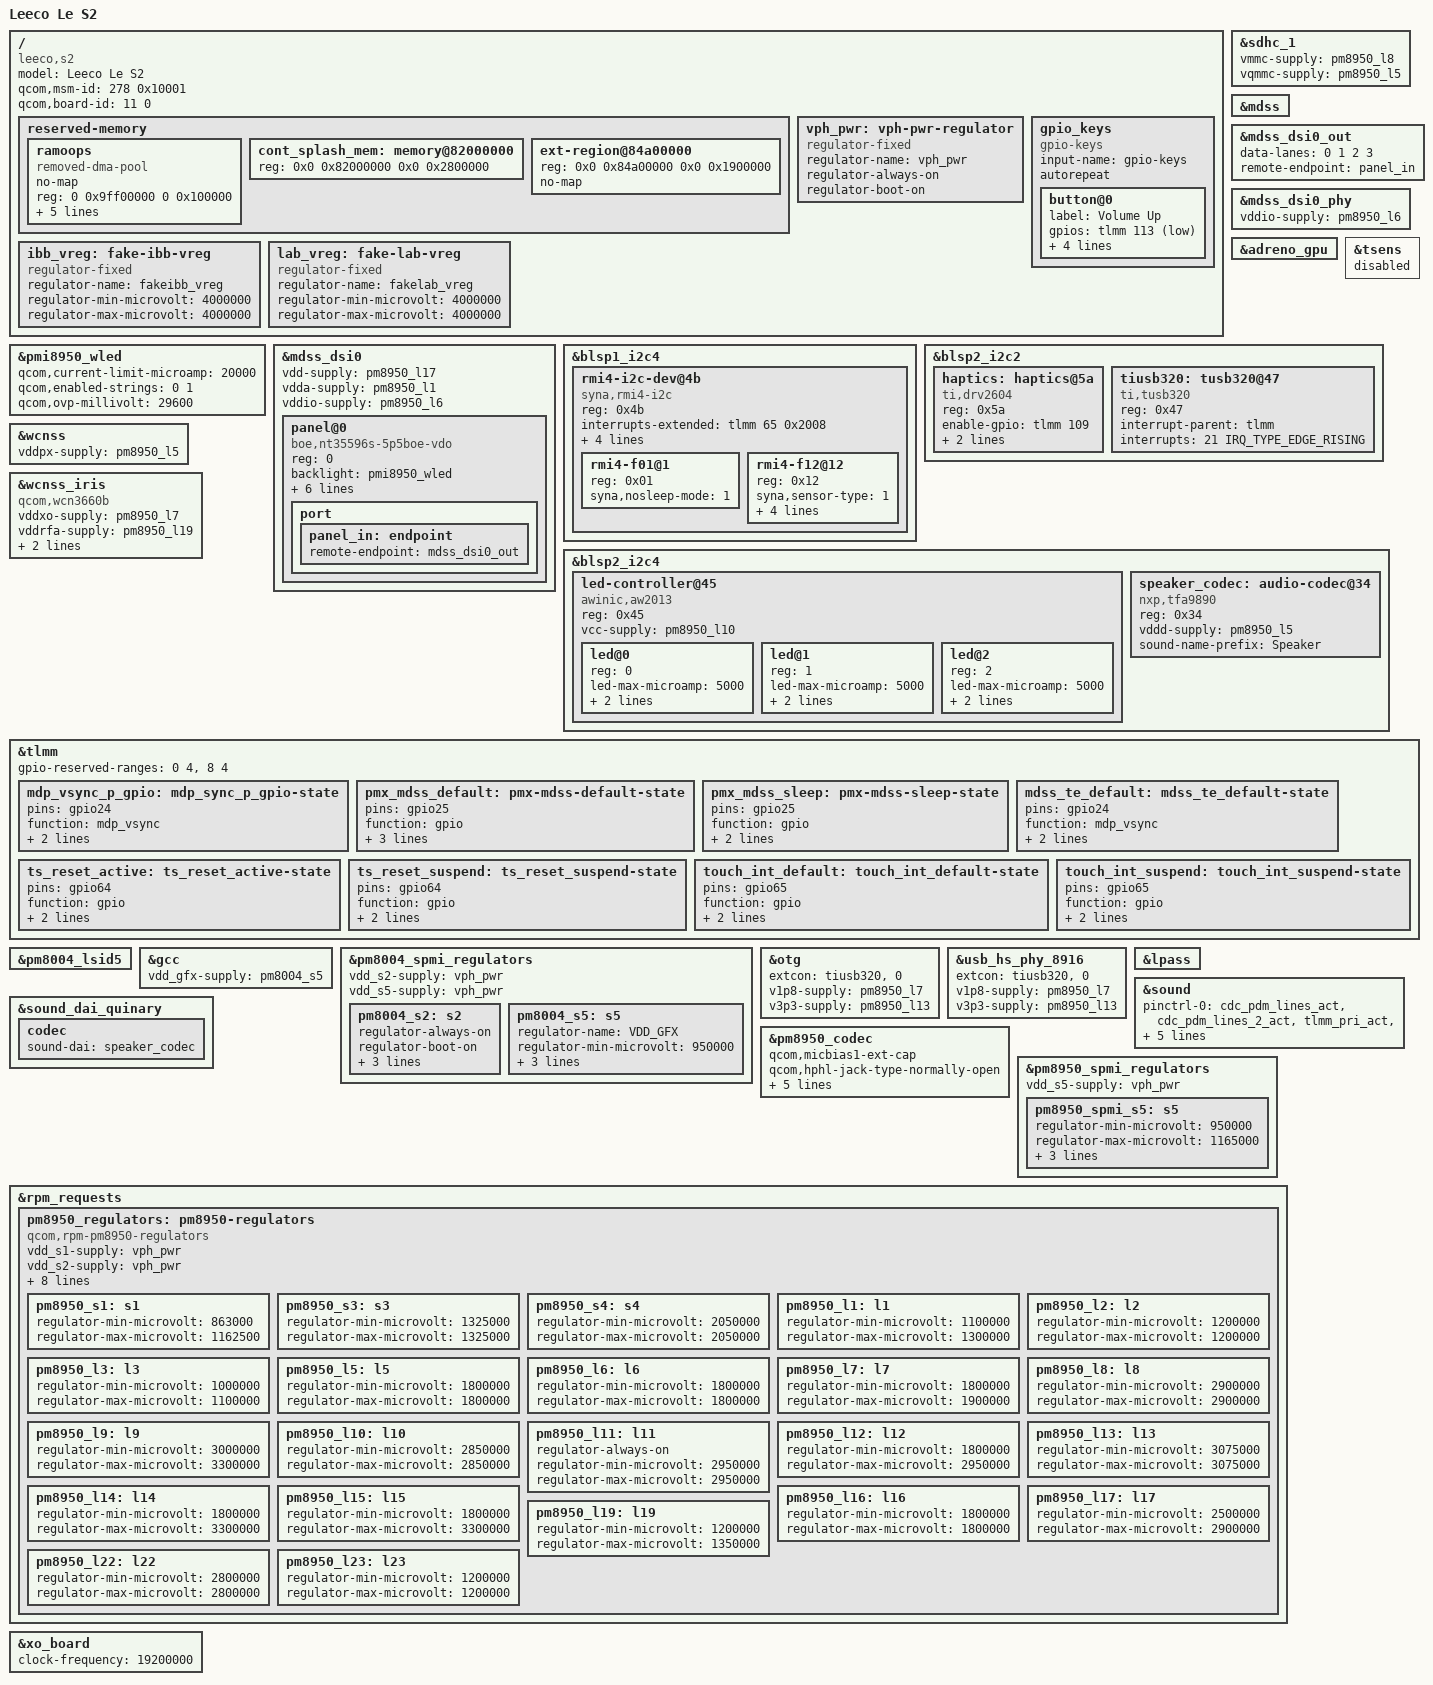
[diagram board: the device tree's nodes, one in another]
// SPDX-License-Identifier: BSD-3-Clause
/dts-v1/;
#include "msm8976.dtsi"
#include "pm8950.dtsi"
#include "pm8004.dtsi"
#include "pmi8950.dtsi"
#include <dt-bindings/interrupt-controller/irq.h>
#include <dt-bindings/gpio/gpio.h>
#include <dt-bindings/input/gpio-keys.h>
#include <dt-bindings/input/input.h>
#include <dt-bindings/input/linux-event-codes.h>
#include <dt-bindings/pinctrl/qcom,pmic-gpio.h>
#include <dt-bindings/leds/common.h>
#include <dt-bindings/input/ti-drv260x.h>

/ {
	model = "Leeco Le S2";
	compatible = "leeco,s2", "qcom,msm8976";

	qcom,msm-id = <278 0x10001>;
	qcom,board-id = <11 0>;

	reserved-memory {
		ramoops {
			compatible = "removed-dma-pool", "ramoops";
			no-map;
			reg = <0 0x9ff00000 0 0x100000>;
			record-size = <0x10000>;
			console-size = <0x60000>;
			ftrace-size = <0x10000>;
			pmsg-size = <0x20000>;
			ecc-size = <16>;
			status = "okay";
		};

		/delete-node/ memory@83000000;
		
		cont_splash_mem: memory@82000000 {
			reg = <0x0 0x82000000 0x0 0x2800000>;
		};
		
		/delete-node/ ext-region@85b00000;
		 ext-region@84a00000 {
			reg = <0x0 0x84a00000 0x0 0x1900000>;
			no-map;
		};

	};

	vph_pwr: vph-pwr-regulator {
		compatible = "regulator-fixed";
		regulator-name = "vph_pwr";
		regulator-always-on;
		regulator-boot-on;
	};

	gpio_keys {
		compatible = "gpio-keys";
		input-name = "gpio-keys";
		#address-cells = <1>;
		#size-cells = <0>;
		autorepeat;

		button@0 {
			label = "Volume Up";
			gpios = <&tlmm 113 GPIO_ACTIVE_LOW>;
			linux,input-type = <EV_KEY>;
			linux,code = <KEY_VOLUMEUP>;
			wakeup-source;
			debounce-interval = <15>;
		};
	};
	ibb_vreg: fake-ibb-vreg {
		compatible = "regulator-fixed";
		regulator-name = "fakeibb_vreg";
		regulator-min-microvolt = <4000000>;
		regulator-max-microvolt = <4000000>;
	};
	lab_vreg: fake-lab-vreg {
		compatible = "regulator-fixed";
		regulator-name = "fakelab_vreg";
		regulator-min-microvolt = <4000000>;
		regulator-max-microvolt = <4000000>;
	};

};

&sdhc_1 {
	vmmc-supply = <&pm8950_l8>;
	vqmmc-supply = <&pm8950_l5>;
	
	status = "okay";
};

&pmi8950_wled {
	status = "okay";

	qcom,current-limit-microamp = <20000>;
	qcom,enabled-strings = <0 1>;
	qcom,ovp-millivolt = <29600>;
};
&mdss {
	status = "okay";
};

&mdss_dsi0 {
	panel@0 {
		compatible = "boe,nt35596s-5p5boe-vdo";
		reg = <0>;
		backlight = <&pmi8950_wled>;

		supply-names = "vsp", "vsn";
		vsp-supply = <&lab_vreg>;
		vsn-supply = <&ibb_vreg>;

		reset-gpios = <&tlmm 25 GPIO_ACTIVE_LOW>;

		pinctrl-names = "default", "sleep";
		pinctrl-0 = <&pmx_mdss_default &mdss_te_default>;
		pinctrl-1 = <&pmx_mdss_sleep &mdss_te_default>;

		port {
			panel_in: endpoint {
				remote-endpoint = <&mdss_dsi0_out>;
			};
		};
	};
};


&mdss_dsi0_out {
	data-lanes = <0 1 2 3>;
	remote-endpoint = <&panel_in>;
};


&mdss_dsi0_phy {
	status = "okay";
	vddio-supply = <&pm8950_l6>;
};

&mdss_dsi0 {

	vdd-supply = <&pm8950_l17>;
	vdda-supply = <&pm8950_l1>;
	vddio-supply = <&pm8950_l6>;
};

&adreno_gpu {
	status = "okay";
};

&tsens {
status = "disabled";
};

&blsp1_i2c4 {
	status = "okay";

	rmi4-i2c-dev@4b {
		reg = <0x4b>;
		compatible = "syna,rmi4-i2c";
		interrupts-extended = <&tlmm 65 0x2008>;
		#address-cells = <1>;
		#size-cells = <0>;

		vdd-supply = <&pm8950_l17>;
		vio-supply = <&pm8950_l6>;
	
		syna,reset-delay-ms = <100>;
		syna,startup-delay-ms = <500>;
		rmi4-f01@1 {
			reg = <0x01>;
			syna,nosleep-mode = <1>;
		};

		rmi4-f12@12 {
			reg = <0x12>;
			syna,sensor-type = <1>;
			syna,clip-x-low = <0>;
			syna,clip-x-high = <1080>;
			syna,clip-y-low = <0>;
			syna,clip-y-high = <1920>;
		};
	};
};

&blsp2_i2c2 {

	status = "okay";
	
	haptics: haptics@5a {
		compatible = "ti,drv2604";
		reg = <0x5a>;
		enable-gpio = <&tlmm 109 GPIO_ACTIVE_HIGH>;
		mode = <DRV260X_LRA_MODE>;
		library-sel = <DRV260X_LIB_LRA>;
	};

	tiusb320: tusb320@47 {
		compatible = "ti,tusb320";
		reg = <0x47>;
		interrupt-parent = <&tlmm>;
		interrupts = <21 IRQ_TYPE_EDGE_RISING>;
        };
};

&blsp2_i2c4 {
	status = "okay";
	led-controller@45 {
		#address-cells = <1>;
		#size-cells = <0>;

		compatible = "awinic,aw2013";
		reg = <0x45>;
		vcc-supply = <&pm8950_l10>;

		led@0 {
			reg = <0>;
			led-max-microamp = <5000>;
			function = LED_FUNCTION_INDICATOR;
			color = <LED_COLOR_ID_RED>;
		};
		led@1 {
			reg = <1>;
			led-max-microamp = <5000>;
			function = LED_FUNCTION_INDICATOR;
			color = <LED_COLOR_ID_GREEN>;
		};
		led@2 {
			reg = <2>;
			led-max-microamp = <5000>;
			function = LED_FUNCTION_INDICATOR;
			color = <LED_COLOR_ID_BLUE>;
		};
	};
	
	speaker_codec: audio-codec@34 {
		compatible = "nxp,tfa9890";
		reg = <0x34>;
		vddd-supply = <&pm8950_l5>;
		sound-name-prefix = "Speaker";
		#sound-dai-cells = <0>;
	};
};


&wcnss {
	status = "okay";
	vddpx-supply = <&pm8950_l5>;
};

&wcnss_iris {
	compatible = "qcom,wcn3660b";

	vddxo-supply = <&pm8950_l7>;
	vddrfa-supply = <&pm8950_l19>;
	vddpa-supply = <&pm8950_l9>;
	vdddig-supply = <&pm8950_l5>;
};

&tlmm {
	gpio-reserved-ranges = <0 4>, <8 4>;

	mdp_vsync_p_gpio: mdp_sync_p_gpio-state {
		pins = "gpio24";
		function = "mdp_vsync";
		drive-strength = <2>;
		bias-disable;
	};


	pmx_mdss_default: pmx-mdss-default-state {
		pins = "gpio25";
		function = "gpio";
		drive-strength = <8>;
		bias-disable;
		output-high;
	};

	pmx_mdss_sleep: pmx-mdss-sleep-state {
		pins = "gpio25";
		function = "gpio";
		drive-strength = <2>;
		bias-pull-down;
	};

	mdss_te_default: mdss_te_default-state {
			pins = "gpio24";
			function = "mdp_vsync";
			drive-strength = <2>;
			bias-pull-down;
		};
		
	ts_reset_active: ts_reset_active-state {
		pins = "gpio64";
		function = "gpio";
		drive-strength = <8>;
		bias-pull-up;
	};

	ts_reset_suspend: ts_reset_suspend-state {
		pins = "gpio64";
		function = "gpio";
		drive-strength = <2>;
		bias-pull-down;
	};

	touch_int_default: touch_int_default-state {
		pins = "gpio65";
		function = "gpio";
		drive-strength = <8>;
		bias-pull-up;
	};

	touch_int_suspend: touch_int_suspend-state {
		pins = "gpio65";
		function = "gpio";
		drive-strength = <2>;
		bias-pull-down;
	};
};

&pm8004_lsid5 {
	status = "okay";
};

&gcc {
	vdd_gfx-supply = <&pm8004_s5>;
};

&pm8004_spmi_regulators {
	vdd_s2-supply = <&vph_pwr>;
	vdd_s5-supply = <&vph_pwr>;
	status = "okay";
	
	pm8004_s2: s2 {
		regulator-always-on;
		regulator-boot-on;
		regulator-name = "vdd_apc1";
		regulator-min-microvolt = <950000>;
		regulator-max-microvolt = <1165000>;
	};

	pm8004_s5: s5 {
		regulator-name = "VDD_GFX";
		regulator-min-microvolt = <950000>;
		regulator-max-microvolt = <1165000>;
		regulator-enable-ramp-delay = <500>;
		regulator-always-on;

	};
};

&otg {
	status = "okay";
	extcon = <&tiusb320>,<0>;
	v1p8-supply = <&pm8950_l7>;
	v3p3-supply = <&pm8950_l13>;
};

&usb_hs_phy_8916 {

	status = "okay";
	extcon = <&tiusb320>,<0>;
	v1p8-supply = <&pm8950_l7>;
	v3p3-supply = <&pm8950_l13>;
};

&lpass {
	status= "okay";
};

&sound {
	status= "okay";

	pinctrl-names = "default", "sleep";
	pinctrl-0 = <&cdc_pdm_lines_act &cdc_pdm_lines_2_act  &tlmm_pri_act &cross_con_sus>;
	pinctrl-1 = <&cdc_pdm_lines_sus &cdc_pdm_lines_2_sus  &tlmm_pri_sus &cross_con_act>;
	model = "leeco-s2";
};

&sound_dai_quinary {
	status = "okay";

	codec {
		sound-dai = <&speaker_codec>;
	};
};

&pm8950_codec {
	status="okay";
	qcom,micbias1-ext-cap;
	qcom,hphl-jack-type-normally-open;
	qcom,mbhc-vthreshold-low = <75 150 237 450 500>;
	qcom,mbhc-vthreshold-high = <75 150 237 450 500>;
	vdd-cdc-io-supply = <&pm8950_l5>;
	vdd-cdc-tx-rx-cx-supply = <&pm8950_s4>;
	vdd-micbias-supply = <&pm8950_l13>;
};

&pm8950_spmi_regulators {
	vdd_s5-supply = <&vph_pwr>;

	/* Cluster 0 supply */
	pm8950_spmi_s5: s5 {
	
		regulator-min-microvolt = <950000>;
		regulator-max-microvolt = <1165000>;
		regulator-name = "vdd_apc0";
		regulator-always-on;
		regulator-boot-on;
	};
};

&rpm_requests {

	pm8950_regulators: pm8950-regulators {
		compatible = "qcom,rpm-pm8950-regulators";
		
		vdd_s1-supply = <&vph_pwr>;
		vdd_s2-supply = <&vph_pwr>;
		vdd_s3-supply = <&vph_pwr>;
		vdd_s4-supply = <&vph_pwr>;
		vdd_s6-supply = <&vph_pwr>;
		vdd_l1_l19-supply = <&pm8950_s3>;
		vdd_l2_l23-supply = <&pm8950_s3>;
		vdd_l3-supply = <&pm8950_s3>;
		vdd_l5_l6_l7_l16-supply = <&pm8950_s4>;
		vdd_l8_l11_l12_l17_l22-supply = <&vph_pwr>;
		
		pm8950_s1: s1 {
			regulator-min-microvolt = <863000>;
			regulator-max-microvolt = <1162500>;	
		};
	
		pm8950_s3: s3 {
			regulator-min-microvolt = <1325000>;
			regulator-max-microvolt = <1325000>;
		};
	
		pm8950_s4: s4 {
			regulator-min-microvolt = <2050000>;
			regulator-max-microvolt = <2050000>;
		};
	
		pm8950_l1: l1 {
			regulator-min-microvolt = <1100000>;
			regulator-max-microvolt = <1300000>;
		};
	
		pm8950_l2: l2 {
			regulator-min-microvolt = <1200000>;
			regulator-max-microvolt = <1200000>;
		};
	
		pm8950_l3: l3 {
			regulator-min-microvolt = <1000000>;
			regulator-max-microvolt = <1100000>;
		};
	
		pm8950_l5: l5 { 
			regulator-min-microvolt = <1800000>;
			regulator-max-microvolt = <1800000>;
		};
	
		pm8950_l6: l6 {
			regulator-min-microvolt = <1800000>;
			regulator-max-microvolt = <1800000>;
		};
		
		pm8950_l7: l7 {
			regulator-min-microvolt = <1800000>;
			regulator-max-microvolt = <1900000>;
		};
		
		pm8950_l8: l8 {
			regulator-min-microvolt = <2900000>;
			regulator-max-microvolt = <2900000>;
		};
	
		pm8950_l9: l9 { 
			regulator-min-microvolt = <3000000>;
			regulator-max-microvolt = <3300000>;
		};
	
		pm8950_l10: l10 {
			regulator-min-microvolt = <2850000>;
			regulator-max-microvolt = <2850000>;
		};
	
		pm8950_l11: l11 {
			regulator-always-on;
			regulator-min-microvolt = <2950000>;
			regulator-max-microvolt = <2950000>;
		};
	
		pm8950_l12: l12 {
			regulator-min-microvolt = <1800000>;
			regulator-max-microvolt = <2950000>;
		};
	
		pm8950_l13: l13 {
			regulator-min-microvolt = <3075000>;
			regulator-max-microvolt = <3075000>;
		};
	
		pm8950_l14: l14 {
			regulator-min-microvolt = <1800000>;
			regulator-max-microvolt = <3300000>;
		};
	
		pm8950_l15: l15 {
			regulator-min-microvolt = <1800000>;
			regulator-max-microvolt = <3300000>;
		};
	
		pm8950_l16: l16 {
			regulator-min-microvolt = <1800000>;
			regulator-max-microvolt = <1800000>;
		};
	
		pm8950_l17: l17 {
			regulator-min-microvolt = <2500000>;
			regulator-max-microvolt = <2900000>;
		};
	
		pm8950_l19: l19 {
			regulator-min-microvolt = <1200000>;
			regulator-max-microvolt = <1350000>;
		};
	
		pm8950_l22: l22 {
			regulator-min-microvolt = <2800000>;
			regulator-max-microvolt = <2800000>;
		};
	
		pm8950_l23: l23 {
			regulator-min-microvolt = <1200000>;
			regulator-max-microvolt = <1200000>;
		};
	};
};
&xo_board {
	clock-frequency = <19200000>;
};
